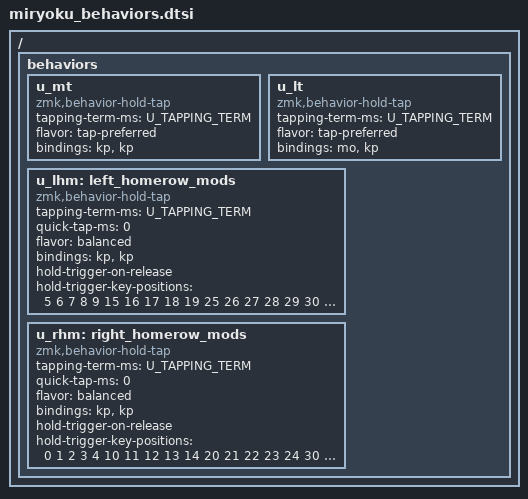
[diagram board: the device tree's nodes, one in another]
// Copyright 2022 Manna Harbour
// https://github.com/manna-harbour/miryoku

/ {
  behaviors {
    u_mt: u_mt {
      compatible = "zmk,behavior-hold-tap";
      #binding-cells = <2>;
      tapping-term-ms = <U_TAPPING_TERM>;
      flavor = "tap-preferred";
      bindings = <&kp>, <&kp>;
    };
    u_lt: u_lt {
      compatible = "zmk,behavior-hold-tap";
      #binding-cells = <2>;
      tapping-term-ms = <U_TAPPING_TERM>;
      flavor = "tap-preferred";
      bindings = <&mo>, <&kp>;
    };
    u_lhm: left_homerow_mods {
      compatible = "zmk,behavior-hold-tap";
      #binding-cells = <2>;
      tapping-term-ms = <U_TAPPING_TERM>;
      quick-tap-ms = <0>;
      flavor = "balanced";
      bindings = <&kp>, <&kp>;
      hold-trigger-on-release;
      hold-trigger-key-positions = <5 6 7 8 9 15 16 17 18 19 25 26 27 28 29 30 31 32 33 34 35;
    };
    u_rhm: right_homerow_mods {
      compatible = "zmk,behavior-hold-tap";
      #binding-cells = <2>;
      tapping-term-ms = <U_TAPPING_TERM>;
      quick-tap-ms = <0>;
      flavor = "balanced";
      bindings = <&kp>, <&kp>;
      hold-trigger-on-release;
      hold-trigger-key-positions = <0 1 2 3 4 10 11 12 13 14 20 21 22 23 24 30 31 32 33 34 35;
            }; 
  };
};
